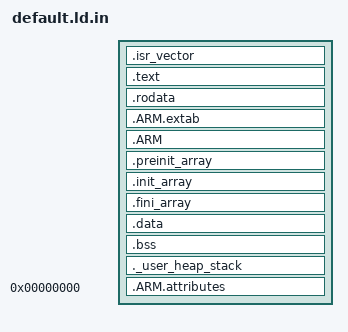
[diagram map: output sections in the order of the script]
/*
 * Generated by mcu_add_linker_script() for @MCU_LD_TARGET@ (@MCU_LD_CHIP@).
 * Do not edit: change the mcu_add_chip() / mcu_add_linker_script() call
 * or pass your own TEMPLATE instead.
 *
 * Symbol names (_sidata, _sdata, _edata, _sbss, _ebss, _estack) match the
 * CMSIS startup files from ST.
 *
 * (READONLY) needs binutils 2.38+. It keeps writable-flagged sections such as
 * .init_array from turning the flash segment into an RWX segment.
 */

ENTRY(Reset_Handler)

_Min_Heap_Size = @MCU_LD_HEAP_SIZE@;
_Min_Stack_Size = @MCU_LD_STACK_SIZE@;

MEMORY
{
@MCU_LD_MEMORY@}

_estack = ORIGIN(@MCU_LD_RAM@) + LENGTH(@MCU_LD_RAM@);

SECTIONS
{
  .isr_vector :
  {
    . = ALIGN(4);
    KEEP(*(.isr_vector))
    . = ALIGN(4);
  } >@MCU_LD_FLASH@

  .text :
  {
    . = ALIGN(4);
    *(.text)
    *(.text*)
    *(.glue_7)
    *(.glue_7t)
    *(.eh_frame)
    KEEP(*(.init))
    KEEP(*(.fini))
    . = ALIGN(4);
    _etext = .;
  } >@MCU_LD_FLASH@

  .rodata :
  {
    . = ALIGN(4);
    *(.rodata)
    *(.rodata*)
    . = ALIGN(4);
  } >@MCU_LD_FLASH@

  .ARM.extab (READONLY) :
  {
    *(.ARM.extab* .gnu.linkonce.armextab.*)
  } >@MCU_LD_FLASH@

  .ARM (READONLY) :
  {
    __exidx_start = .;
    *(.ARM.exidx*)
    __exidx_end = .;
  } >@MCU_LD_FLASH@

  .preinit_array (READONLY) :
  {
    PROVIDE_HIDDEN(__preinit_array_start = .);
    KEEP(*(.preinit_array*))
    PROVIDE_HIDDEN(__preinit_array_end = .);
  } >@MCU_LD_FLASH@

  .init_array (READONLY) :
  {
    PROVIDE_HIDDEN(__init_array_start = .);
    KEEP(*(SORT(.init_array.*)))
    KEEP(*(.init_array*))
    PROVIDE_HIDDEN(__init_array_end = .);
  } >@MCU_LD_FLASH@

  .fini_array (READONLY) :
  {
    PROVIDE_HIDDEN(__fini_array_start = .);
    KEEP(*(SORT(.fini_array.*)))
    KEEP(*(.fini_array*))
    PROVIDE_HIDDEN(__fini_array_end = .);
  } >@MCU_LD_FLASH@

  /* Initialized data: runs from RAM, loaded from flash by the startup code. */
  _sidata = LOADADDR(.data);
  .data :
  {
    . = ALIGN(4);
    _sdata = .;
    *(.data)
    *(.data*)
    *(.RamFunc)
    *(.RamFunc*)
    . = ALIGN(4);
    _edata = .;
  } >@MCU_LD_RAM@ AT> @MCU_LD_FLASH@

  .bss (NOLOAD) :
  {
    . = ALIGN(4);
    _sbss = .;
    __bss_start__ = _sbss;
    *(.bss)
    *(.bss*)
    *(COMMON)
    . = ALIGN(4);
    _ebss = .;
    __bss_end__ = _ebss;
  } >@MCU_LD_RAM@

  /* Fails the link if heap + stack do not fit after .bss. */
  ._user_heap_stack (NOLOAD) :
  {
    . = ALIGN(8);
    PROVIDE(end = .);
    PROVIDE(_end = .);
    . = . + _Min_Heap_Size;
    . = . + _Min_Stack_Size;
    . = ALIGN(8);
  } >@MCU_LD_RAM@

  /* Extra writable regions (NOLOAD, not initialized by startup). */
@MCU_LD_EXTRA_SECTIONS@
  .ARM.attributes 0 : { *(.ARM.attributes) }
}
